# XMC register map
Vendor: Texas Instruments
Peripheral module from a debugger description file (folder omap36xx).
Registers are 32-bit, access not given, reset values left out (the file's numbers can be read two ways) unless marked. A register's access mark holds for its fields unless they carry their own. Offsets are as the file gives them; lines under a group give offsets from that group; [hi:lo] are bit positions; {n}, {i} and the like mark numbered series; 'fields as' and 'values as' point back to an identical list; <NAME> marks a mode.

## XMC
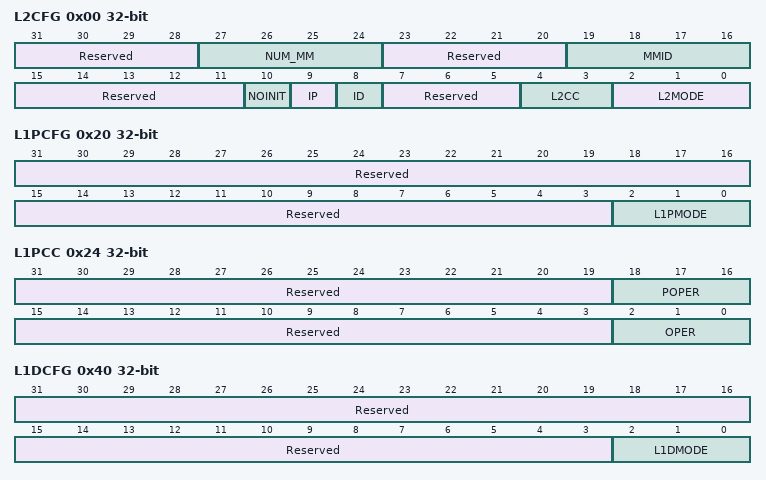
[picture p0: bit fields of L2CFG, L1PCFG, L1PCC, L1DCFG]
0x00 L2CFG access per field — L2 cache configuration register
  [31:28] Reserved ro — Write 0s for future compatibility. Read returns 0.
  [27:24] NUM_MM ro — Number of megamodules -1 (always 0 for IVA2)
  [23:20] Reserved ro — Write 0s for future compatibility. Read returns 0.
  [19:16] MMID ro — Megamodule ID (always 0x0 for IVA2)
  [15:11] Reserved wo — Write 0s for future compatibility. Read returns 0.
  [10] NOINIT wo — No init upon cache config: when written '1', cache config is restored without re-initializing cache context (tags, validity bits) (this is assumed here that the restored cache settings are the same as prior to the execution of the IDLE instruction) when written '0', cache context is re-initialized (cache content is indirectly lost) this bit is always read as 0
  [9] IP wo — Global L1P invalidate (for backward compatibility,deprecated)
  [8] ID wo — Global L1D invalidate (for backward compatibility,deprecated)
  [7:5] Reserved wo — Write 0s for future compatibility. Read returns 0.
  [4:3] L2CC rw — L2 cache control
    0=L2 cache operates normally; 1=L2 Cache is frozen; 2=L2 cache is bypassed
  [2:0] L2MODE rw — L2 Configuration Register
    0=0KB of L2 Cache; 1=32KB of L2 Cache; 2=64KB of L2 Cache
0x20 L1PCFG rw
  [31:3] Reserved — Write 0s for future compatibility. Read returns 0.
  [2:0] L1PMODE — L1P Configuration Register
    0=0KB of L1P Cache; 1=4KB of L1P Cache; 2=8KB of L1P Cache; 3=16KB of L1P Cache; 4=Maximum cache (32KB of L1P Cache)
0x24 L1PCC access per field — L1P Configuration Register
  [31:19] Reserved ro — Write 0s for future compatibility. Read returns 0.
  [18:16] POPER ro — Previous value of the OPER field
    0=POPER_0_r (L1P cache operates normally); 1=POPER_1_r (L1P Cache is frozen)
  [15:3] Reserved rw — Write 0s for future compatibility. Read returns 0.
  [2:0] OPER rw — DMC operation control
    0=L1P cache operates normally; 1=L1P Cache is frozen
0x40 L1DCFG rw — L1D resets to Maximal cache mode using dmc_default_cachemode tie-off input.
  [31:3] Reserved — Write 0s for future compatibility. Read returns 0.
  [2:0] L1DMODE — L1D Configuration Register
    0=0KB of L1D Cache; 1=4KB of L1D Cache; 2=8KB of L1D Cache; 3=16KB of L1D Cache; 4=32KB of L1D Cache; 7=Maximum cache (maps to 32KB of L1D Cache)
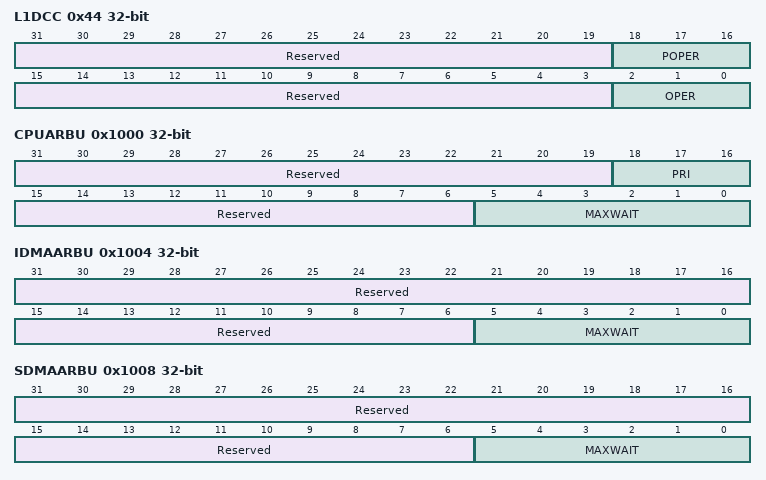
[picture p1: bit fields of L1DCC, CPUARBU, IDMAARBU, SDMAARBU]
0x44 L1DCC access per field — L1D Configuration Register
  [31:19] Reserved ro — Write 0s for future compatibility. Read returns 0.
  [18:16] POPER ro — Previous value of the OPER field
    0=POPER_0_r (L1D cache operates normally); 1=POPER_1_r (L1D Cache is frozen)
  [15:3] Reserved rw — Write 0s for future compatibility. Read returns 0.
  [2:0] OPER rw — DMC operation control
    0=L1D cache operates normally; 1=L1D Cache is frozen
0x1000 CPUARBU rw
  [31:19] Reserved — Write 0s for future compatibility. Read returns 0.
  [18:16] PRI — Priority
    0=Highest priority; 1=2nd highest priority; 2=3rd highest priority; {v}={v+1}th highest priority (v=3..6); 7=Lowest priority
  [15:6] Reserved — Write 0s for future compatibility. Read returns 0.
  [5:0] MAXWAIT — Maximum Wait time (in UMC/EMC cycles)
    0=Always stalls due to higher priority requestor; 1=Maximum wait of 1 cycles (1/2 = 50% access); 2=Maximum wait of 2 cycles (1/3 = 33% access); 4=Maximum wait of 4 cycles (1/5 = 20% access); 8=Maximum wait of 8 cycles (1/9 = 11% access); 16=Maximum wait of 16 cycles (1/17 = 6% access); 32=Maximum wait of 32 cycles (1/33 = 3% access)
0x1004 IDMAARBU rw
  [31:6] Reserved — Write 0s for future compatibility. Read returns 0.
  [5:0] MAXWAIT — Maximum Wait time (in UMC/EMC cycles)
    values as CPUARBU.MAXWAIT
0x1008 SDMAARBU rw
  fields as IDMAARBU
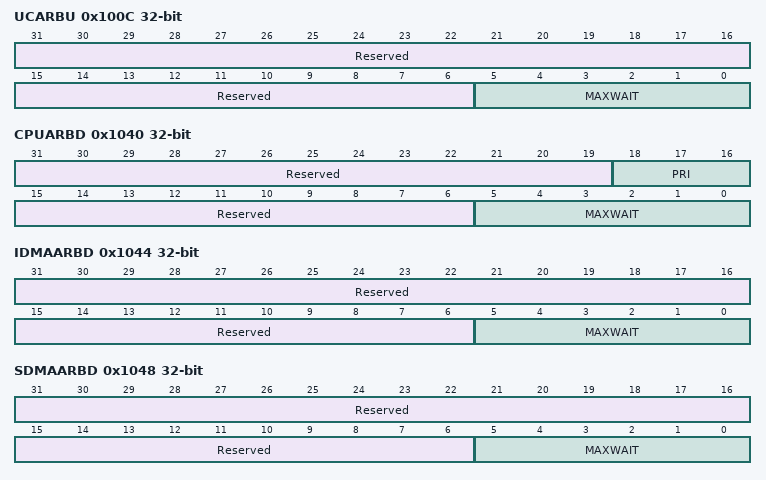
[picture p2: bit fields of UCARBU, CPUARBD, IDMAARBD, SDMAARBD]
0x100C UCARBU rw
  fields as IDMAARBU
0x1040 CPUARBD rw — CPU Arb Control
  fields as CPUARBU
0x1044 IDMAARBD rw
  fields as IDMAARBU
0x1048 SDMAARBD rw
  fields as IDMAARBU
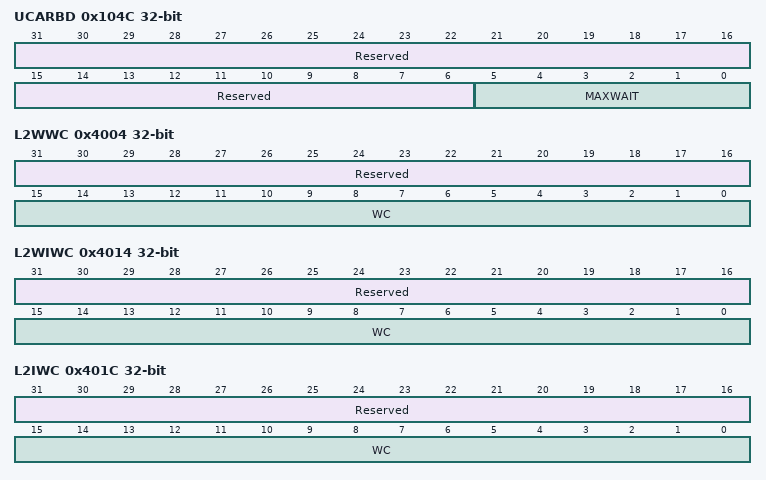
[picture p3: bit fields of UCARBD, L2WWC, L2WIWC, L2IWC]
0x104C UCARBD rw
  [31:6] Reserved — Write 0s for future compatibility. Read returns 0.
  [5:0] MAXWAIT — Maximum Wait time (in UMC/EMC cycles)
    0=Always stalls due to higher priority requestor; 1=Maximum wait of 1 cycles (1/2 = 50% access); 2=max wait of 2 cycles (1/3 = 33% access); 4=Maximum wait of 4 cycles (1/5 = 20% access); 8=Maximum wait of 8 cycles (1/9 = 11% access); 16=Maximum wait of 16 cycles (1/17 = 6% access); 32=Maximum wait of 32 cycles (1/33 = 3% access)
0x4000 L2WBAR wo — L2 block writeback base address
  [31:0] ADDR — Block base address
0x4004 L2WWC rw
  [31:16] Reserved — Write 0s for future compatibility. Read returns 0.
  [15:0] WC — Number of 32-bit words in the block
0x4010 L2WIBAR wo — L2 block wbinv base address
  [31:0] ADDR — Block base address
0x4014 L2WIWC rw
  fields as L2WWC
0x4018 L2IBAR wo
  [31:0] ADDR
0x401C L2IWC rw
  fields as L2WWC
0x4020 L1PIBAR wo — L1P Block Invalidate Base Address Register
  [31:0] ADDR — Block base address
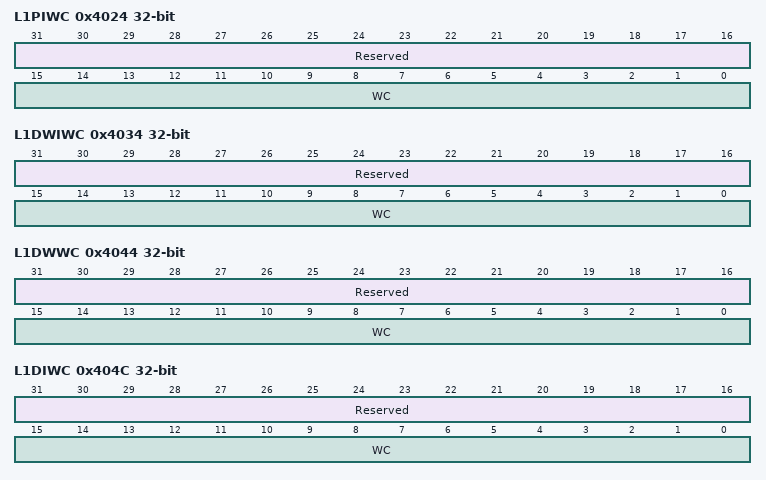
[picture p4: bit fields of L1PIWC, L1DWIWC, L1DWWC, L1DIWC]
0x4024 L1PIWC rw — L1P Block Invalidate Word Count
  fields as L2WWC
0x4030 L1DWIBAR wo
  [31:0] ADDR — Block base address
0x4034 L1DWIWC rw — L1D Block Wb-Inv Word Count
  fields as L2WWC
0x4040 L1DWBAR wo — L1D Block Writeback Base Address Register
  [31:0] ADDR — Block base address
0x4044 L1DWWC rw — L1D Block Writeback Word Count
  fields as L2WWC
0x4048 L1DIBAR wo — L1D Block Invalidate Base Address Register
  [31:0] ADDR — Block base address
0x404C L1DIWC rw — L1D Block Invalidate Word Count
  fields as L2WWC
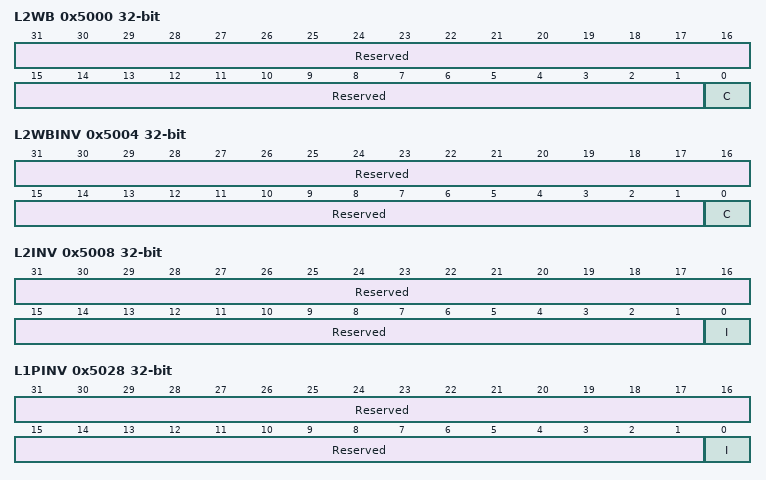
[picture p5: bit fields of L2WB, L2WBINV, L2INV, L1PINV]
0x5000 L2WB rw — L2 global writeback
  [31:1] Reserved — Write 0s for future compatibility. Read returns 0.
  [0] C — L2 global write-back control
    0=C_0_r (Read 0: Previous L2 global write-back has completed); 0=C_0_w (Write 0: No effect); 1=C_1_r (Read 1: Previous L2 global write-back has not completed); 1=C_1_w (Write 1: Initiates an L2 global write-back(L1P Effect: No effect. L1D Effect: All updated data written back to L2/external, but left valid in L1D. L2 Effect: All updated data written back externally, but left valid in L2 cache. ))
0x5004 L2WBINV rw — L2 global writeback invalidate
  [31:1] Reserved — Write 0s for future compatibility. Read returns 0.
  [0] C — L2 global write-back/invalidate command:
    0=C_0_w (No effect); 1=C_1_w (Initiates an L2 global write-back/invalidate(L1P Effect: All lines invalidated in L1P. L1D Effect: All updated data written back to L2/external. All lines invalidated within L1D. L2 Effect: All updated data written back externally. All lines invalidated in L2).); 0=C_0_r (Previous L2 global write-back/invalidate has completed); 1=C_1_r (Previous L2 global write-back/invalidate has not completed)
0x5008 L2INV rw — L2 global invalidate
  [31:1] Reserved — Write 0s for future compatibility. Read returns 0.
  [0] I — L2 global invalidate command:
    0=I_0_w (No effect); 1=I_1_w (Initiates an L2 global invalidate(L1P Effect: All lines invalidated in L1P. L1D Effect: All lines invalidated in L1D. Updated data is dropped. L2 Effect: All lines invalidated in L2. Updated data is dropped).); 0=I_0_r (Previous L2 global invalidate has completed); 1=I_1_r (Previous L2 global invalidate has notcompleted)
0x5028 L1PINV rw — L1P Global Invalidate
  [31:1] Reserved — Write 0s for future compatibility. Read returns 0.
  [0] I — L1P global invalidate command:
    0=I_0_w (No effect); 1=I_1_w (Initiates an L1P global invalidate); 0=I_0_r (Previous L1P global invalidate has completed); 1=I_1_r (Previous L1P global invalidate has notcompleted)
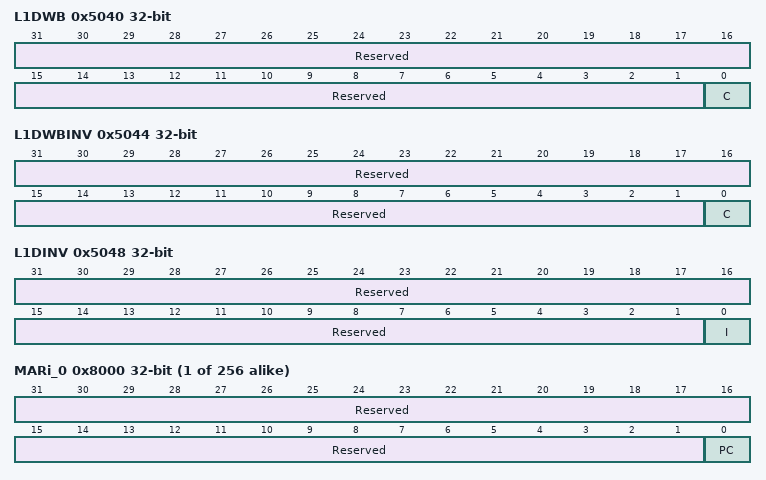
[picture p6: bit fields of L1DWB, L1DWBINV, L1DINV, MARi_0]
0x5040 L1DWB rw — L1D Global Writeback
  [31:1] Reserved — Write 0s for future compatibility. Read returns 0.
  [0] C — L1D global write-back command:
    0=C_0_w (No effect); 1=C_1_w (Initiates an L1D global write-back); 0=C_0_r (Previous L1D global write-back has completed); 1=C_1_r (Previous L1D global write-back has notcompleted)
0x5044 L1DWBINV rw — L1D Global Writeback Invalidate
  [31:1] Reserved — Write 0s for future compatibility. Read returns 0.
  [0] C — L1D global write-back/invalidate command:
    0=C_0_w (No effect); 1=C_1_w (Initiates an L1D global write-back/invalidate); 0=C_0_r (Previous L1D global write-back/invalidate has completed); 1=C_1_r (Previous L1D global write-back/invalidate has not completed)
0x5048 L1DINV rw — L1D Global Invalidate
  [31:1] Reserved — Write 0s for future compatibility. Read returns 0.
  [0] I — L1D global invalidate command:
    0=I_0_w (No effect); 1=I_1_w (Initiates an L1D global invalidate); 0=I_0_r (Previous L1D global invalidate has completed); 1=I_1_r (Previous L1D global invalidate has notcompleted)
{0x8000+4i} MARi_{i} (i=0..255) — Memory Attribute Register i = 0 defines the cacheable memory attribute for Local L2 RAM (fixed) i = 1 to 255 define a cachable memory attribute for 0x0100 0000 memory range starting at 0x0100 0000
  [31:1] Reserved ro — Write 0s for future compatibility. Read returns 0.
  [0] PC — (access RW (R for i=0...15))
    0=PC_0_r (Region is not cached); 1=PC_1_r (Region is cached)
0xA000 L2MPFAR wo — L2 Memory Protection Fault Address Register
  [31:0] ADDR — Block base address
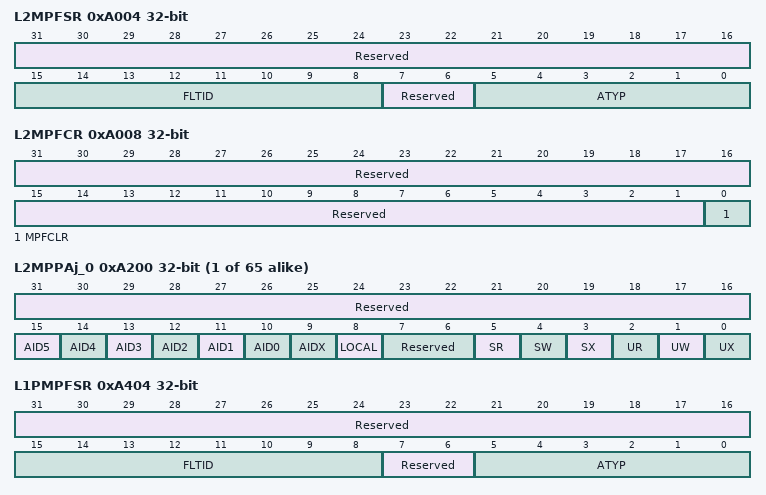
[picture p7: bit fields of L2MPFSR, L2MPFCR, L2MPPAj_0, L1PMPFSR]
0xA004 L2MPFSR ro
  [31:16] Reserved — Write 0s for future compatibility. Read returns 0.
  [15:8] FLTID — Faulted ID:VBUS PrivID of faulting requestor. This field is valid only if LE is zero.
  [7:6] Reserved — Write 0s for future compatibility. Read returns 0.
  [5:0] ATYP — Access type
0xA008 L2MPFCR wo — L2 Memory Protection Fault Command Register
  [31:1] Reserved — Write 0s for future compatibility. Read returns 0.
  [0] MPFCLR — Write 0: No effect Write 1: Clear fault logged information
{0xA200+4i} L2MPPAj_{i} rw (i=0..64) — L2 Memory Protection Attribute Register Addresses for the 16MB page number i
  [31:16] Reserved — Write 0s for future compatibility. Read returns 0.
  [n+10] AID{n} (n=0..5) — 0: ID {n} does not have access permission1: ID {n} has access permission
  [9] AIDX — 0: External access is not permitted1: External access is permitted
  [8] LOCAL — 0: DSP megamodule access is not permitted1: DSP megamodule access is permitted
  [7:6] Reserved — Write 0s for future compatibility.Read returns 0.
  [5] SR — 0: Supervisor Read access is not permitted1: Supervisor Read access is permitted
  [4] SW — 0: Supervisor Write access is not permitted1: Supervisor Write access is permitted
  [3] SX — 0: Supervisor eXecute access is not permitted1: Supervisor eXecute access is permitted
  [2] UR — 0: User Read access is not permitted1: User Read access is permitted
  [1] UW — 0: User Write access is not permitted1: User Write access is permitted
  [0] UX — 0: User eXecute access is not permitted1: User eXecute access is permitted
0xA400 L1PMPFAR ro — PMC
  [31:0] ADDR — Fault Address
0xA404 L1PMPFSR ro — PMC
  [31:16] Reserved — Write 0s for future compatibility. Read returns 0.
  [15:8] FLTID — Faulted ID:VBUS PrivID of faulting requestor. This field is valid only if LE is zero.
  [7:6] Reserved — Write 0s for future compatibility. Read returns 0.
  [5:0] ATYP — Access type
    1=ATYP_1_r (Invalid user program fetch.); 2=ATYP_2_r (Invalid user write); 4=ATYP_4_r (Invalid user read); 8=ATYP_8_r (Invalid supervisor program fetch); 16=ATYP_16_r (Invalid supervisor read); 18=ATYP_18_r (Invalid cache line writeback); 32=ATYP_32_r (Invalid supervisor write); 63=ATYP_63_r (Invalid cache line fill)
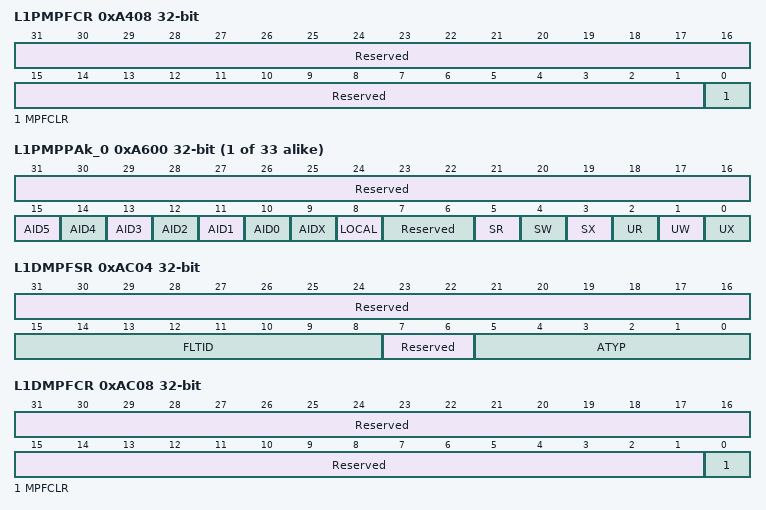
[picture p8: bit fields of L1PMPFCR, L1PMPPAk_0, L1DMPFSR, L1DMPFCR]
0xA408 L1PMPFCR wo — PMC
  fields as L2MPFCR
{0xA600+4i} L1PMPPAk_{i} rw (i=0..32) — L1P Memory Protection Attribute Register Addresses for the 16MB page number i
  fields as L2MPPAj_0
0xAC00 L1DMPFAR ro — L1D Memory Protection Fault Address Register
  [31:0] ADDR — Fault Address
0xAC04 L1DMPFSR ro — L1D Memory Protection Fault Status Register
  fields as L1PMPFSR
0xAC08 L1DMPFCR wo — L1D Memory Protection Fault Command Register
  [31:1] Reserved — Write 0s for future compatibility.Read returns 0.
  [0] MPFCLR — Write 0: No effectWrite 1: Clear fault logged information
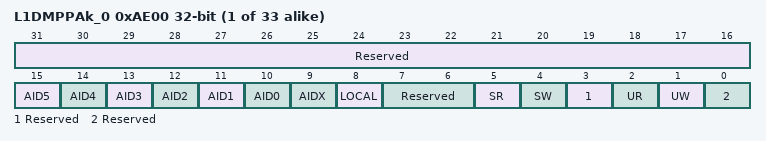
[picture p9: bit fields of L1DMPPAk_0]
{0xAE00+4i} L1DMPPAk_{i} rw (i=0..32) — L1D Memory Protection Attribute Register Addresses for the 16MB page number i
  [31:16] Reserved — Write 0s for future compatibility. Read returns 0.
  [n+10] AID{n} (n=0..5) — 0: ID {n} does not have access permission1: ID {n} has access permission
  [9] AIDX — 0: External access is not permitted1: External access is permitted
  [8] LOCAL — 0: DSP megamodule access is not permitted1: DSP megamodule access is permitted
  [7:6] Reserved — Write 0s for future compatibility.Read returns 0.
  [5] SR — 0: Supervisor Read access is not permitted1: Supervisor Read access is permitted
  [4] SW — 0: Supervisor Write access is not permitted1: Supervisor Write access is permitted
  [3] Reserved — Write 0s for future compatibility. Read returns 0.
  [2] UR — 0: User Read access is not permitted1: User Read access is permitted
  [1] UW — 0: User Write access is not permitted1: User Write access is permitted
  [0] Reserved — Write 0s for future compatibility. Read returns 0.
